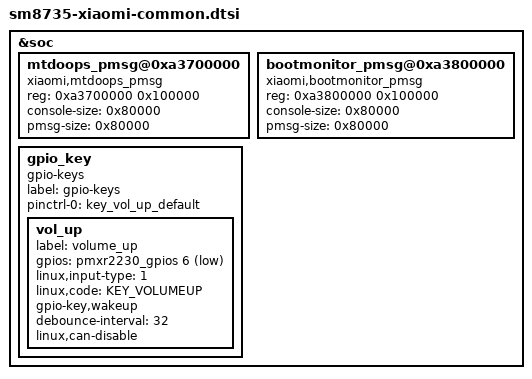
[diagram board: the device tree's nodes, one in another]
#include <dt-bindings/input/input.h>
#include "tuna-mtp.dtsi"

&soc {
	mtdoops_pmsg@0xa3700000 {
		compatible = "xiaomi,mtdoops_pmsg";
		reg = <0xa3700000 0x100000>;
		console-size = <0x80000>;
		pmsg-size = <0x80000>;
	};

	bootmonitor_pmsg@0xa3800000 {
		compatible = "xiaomi,bootmonitor_pmsg";
		reg = <0xa3800000 0x100000>;
		console-size = <0x80000>;
		pmsg-size = <0x80000>;
	};

	gpio_key {
		compatible = "gpio-keys";
		label = "gpio-keys";
		pinctrl-names = "default";
		pinctrl-0 = <&key_vol_up_default>;

		vol_up {
			label = "volume_up";
			gpios = <&pmxr2230_gpios 6 GPIO_ACTIVE_LOW>;
			linux,input-type = <1>;
			linux,code = <KEY_VOLUMEUP>;
			gpio-key,wakeup;
			debounce-interval = <32>;
			linux,can-disable;
		};
	};
};

